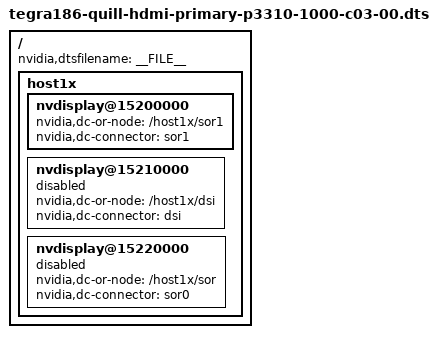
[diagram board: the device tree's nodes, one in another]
/*
 * tegra186-quill-hdmi-primary-p3310-1000-a00-00.dts
 * Device Tree file for Quill to enable single head
 * only with HDMI as primary display
 *
 * Copyright (c) 2017, NVIDIA CORPORATION.  All rights reserved.
 *
 * This program is free software; you can redistribute it and/or modify
 * it under the terms of the GNU General Public License as published by
 * the Free Software Foundation; version 2 of the License.
 *
 * This program is distributed in the hope that it will be useful, but WITHOUT
 * ANY WARRANTY; without even the implied warranty of MERCHANTABILITY or
 * FITNESS FOR A PARTICULAR PURPOSE.  See the GNU General Public License for
 * more details.
 *
 */

#include "tegra186-quill-p3310-1000-c03-00-base.dts"

/ {
	nvidia,dtsfilename = __FILE__;

	host1x {
		nvdisplay@15200000 {
			status = "okay";
			nvidia,dc-or-node = "/host1x/sor1";
			nvidia,dc-connector = <&sor1>;
		};
		nvdisplay@15210000 {
			status = "disabled";
			nvidia,dc-or-node = "/host1x/dsi";
			nvidia,dc-connector = <&dsi>;
		};
		nvdisplay@15220000 {
			status = "disabled";
			nvidia,dc-or-node = "/host1x/sor";
			nvidia,dc-connector = <&sor0>;
		};
	};
};
